# cslr_ectl register map
Vendor: Texas Instruments
Peripheral module from a debugger description file (folder c6472).
Registers are 32-bit, access not given, reset 0x0 unless marked. A register's access mark holds for its fields unless they carry their own. Offsets are as the file gives them; lines under a group give offsets from that group; [hi:lo] are bit positions; {n}, {i} and the like mark numbered series; 'fields as' and 'values as' point back to an identical list; <NAME> marks a mode.

## ECTL — ECTL(Ethernet Multicore Interrupt Combiner Control)
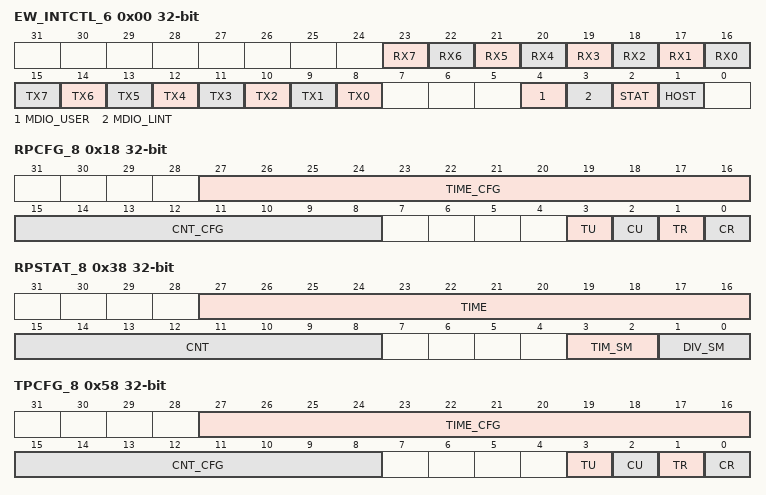
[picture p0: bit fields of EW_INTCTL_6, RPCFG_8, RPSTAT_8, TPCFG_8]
0x00 EW_INTCTL_6 — Emac wrapper interrupt Control Register
  [23] RX7 rw — Controls the generation of the Rx7 interrupt
    0=DISABLE (EMIC receive interrupts are disabled); 1=ENABLE (EMIC receive interrupts are enabled)
  [22] RX6 rw — Controls the generation of the Rx6 interrupt
    0=DISABLE (EMIC receive interrupts are disabled); 1=ENABLE (EMICreceive interrupts are enabled)
  [21] RX5 rw — Controls the generation of the Rx5 interrupt
    values as RX6
  [20] RX4 rw — Controls the generation of the Rx4 interrupt
    values as RX6
  [19] RX3 rw — Controls the generation of the Rx3 interrupt
    values as RX7
  [18] RX2 rw — Controls the generation of the Rx2 interrupt
    values as RX7
  [17] RX1 rw — Controls the generation of the Rx1 interrupt
    values as RX6
  [16] RX0 rw — Controls the generation of the Rx0 interrupt
    values as RX7
  [n+8] TX{n} rw (n=0..7) — Controls the generation of the Tx{n} interrupt
    0=DISABLE (EMIC transmit interrupts are disabled); 1=ENABLE (EMIC transmit interrupts are enabled)
  [4] MDIO_USER rw — Controls the generation of the common interrupt
    0=DISABLE (EMIC MDIO_USER interrupts are disabled); 1=ENABLE (EMIC MDIO_USER interrupts are enabled)
  [3] MDIO_LINT rw — Controls the generation of the common interrupt
    0=DISABLE (EMIC MDIO_LINT interrupts are disabled); 1=ENABLE (EMIC MDIO_LINT interrupts are enabled)
  [2] STAT rw — Controls the generation of the common interrupt
    0=DISABLE (EMIC STAT interrupts are disabled); 1=ENABLE (EMIC STAT interrupts are enabled)
  [1] HOST rw — Controls the generation of the common interrupt
    0=DISABLE (EMIC HOST interrupts are disabled); 1=ENABLE (EMICHOST interrupts are enabled)
0x18 RPCFG_8 — RPIC Register
  [27:16] TIME_CFG rw — Configures the divide by N value
  [15:8] CNT_CFG rw — Configures the time delay value
  [3] TU rw — Enables Write to TIME_CFG
    1=ENABLE (Enables Write to TIME_CFG)
  [2] CU rw — Enables Write to CNT_CFG
    1=ENABLE (Enables Write to CNT_CFG)
  [1] TR rw — Resets the timer Counter
    1=RESET (Resets the Divide by N counter)
  [0] CR rw — Resets the Divide by N counter
    1=RESET (Resets the timer Counter)
0x38 RPSTAT_8 — RPIC Register
  [27:16] TIME ro — Current time delay value
  [15:8] CNT ro — Current Divide by N value
  [3:2] TIM_SM ro — Timed Delay SM is in WAITING State
  [1:0] DIV_SM ro — Divide by N SM is in WAITING state
0x58 TPCFG_8 — RPIC Register
  [27:16] TIME_CFG rw — Configures the time delay value
  [15:8] CNT_CFG rw — Configures theDivide by N value
  [3] TU rw — Enables Write to TIME_CFG
    1=ENABLE (Enables Write to TIME_CFG)
  [2] CU rw — Enables Write to CNT_CFG
    1=ENABLE (Enables Write to CNT_CFG)
  [1] TR rw — Resets the Divide by N counter
    1=RESET (Resets the Divide by N counter)
  [0] CR rw — Resets the timer Counter
    1=RESET (Resets the timer Counter)
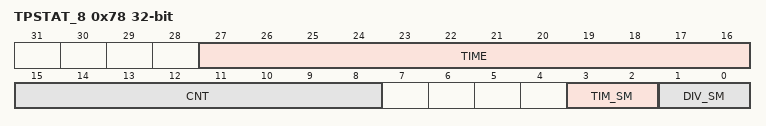
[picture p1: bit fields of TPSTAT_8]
0x78 TPSTAT_8 — RPIC Register
  fields as RPSTAT_8
0x98 PSCFG — Prescalar Config Register
  [15:0] PRESCALE_CFG rw — Contains the Reload value for the prescalar configuration value
